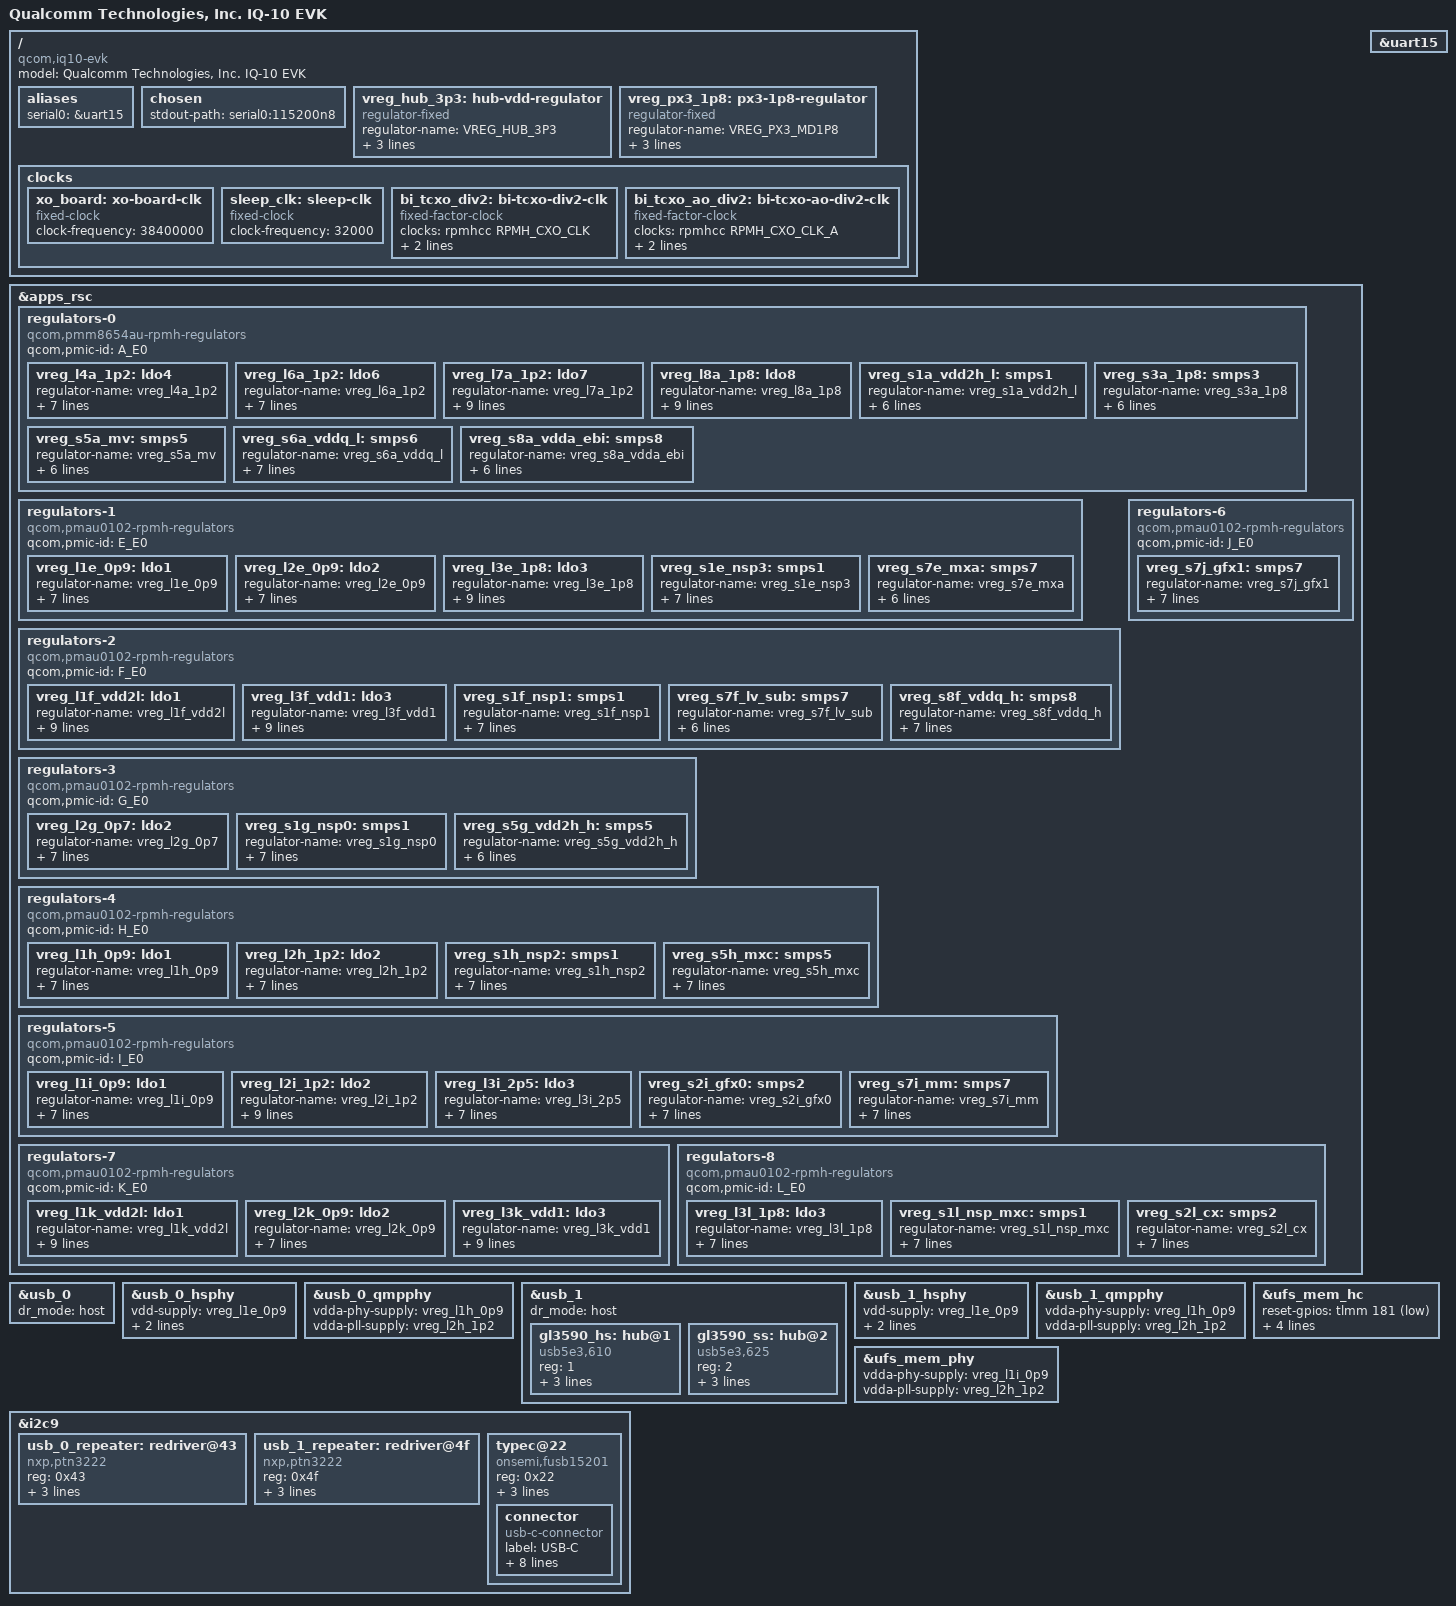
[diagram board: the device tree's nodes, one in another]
// SPDX-License-Identifier: BSD-3-Clause
/*
 * Copyright (c) 2024-2025, Qualcomm Innovation Center, Inc. All rights reserved.
 */

/dts-v1/;

#include <dt-bindings/gpio/gpio.h>
#include <dt-bindings/regulator/qcom,rpmh-regulator.h>
#include <dt-bindings/usb/pd.h>

#include "nord-iq10.dtsi"

/ {
	model = "Qualcomm Technologies, Inc. IQ-10 EVK";
	compatible = "qcom,iq10-evk", "qcom,iq10", "qcom,nord";

	aliases {
		serial0 = &uart15;
	};

	chosen {
		stdout-path = "serial0:115200n8";
	};

	/*
	 * The GL3590 hub's VDD (3.3V) comes from a dedicated always-on board
	 * rail (VREG_PER_3P3) — there is no PMIC LDO behind it.
	 */
	vreg_hub_3p3: hub-vdd-regulator {
		compatible = "regulator-fixed";
		regulator-name = "VREG_HUB_3P3";
		regulator-min-microvolt = <3300000>;
		regulator-max-microvolt = <3300000>;
		regulator-always-on;
	};

	/*
	 * VREG_PX3_MD1P8 (1.8V): TPS6594742 UPMS PMIC SMPS5 output
	 * (VDD_SAIL_PX3_VREG_S1P8). The TPS6594742 is managed by the SAIL
	 * RTOS over SAIL I2C (SGP0/1); the main SoC Linux kernel has no
	 * direct path to it. Describe as a fixed always-on stub — SAIL
	 * firmware enables SMPS5 unconditionally at startup.
	 * Powers: FUSB15201 VDD (U15) and its I2C level shifter VCCA (U17).
	 */
	vreg_px3_1p8: px3-1p8-regulator {
		compatible = "regulator-fixed";
		regulator-name = "VREG_PX3_MD1P8";
		regulator-min-microvolt = <1800000>;
		regulator-max-microvolt = <1800000>;
		regulator-always-on;
	};

	clocks {
		xo_board: xo-board-clk {
			compatible = "fixed-clock";
			clock-frequency = <38400000>;
			#clock-cells = <0>;
		};

		sleep_clk: sleep-clk {
			compatible = "fixed-clock";
			clock-frequency = <32000>;
			#clock-cells = <0>;
		};

		bi_tcxo_div2: bi-tcxo-div2-clk {
			compatible = "fixed-factor-clock";
			#clock-cells = <0>;
			clocks = <&rpmhcc RPMH_CXO_CLK>;
			clock-mult = <1>;
			clock-div = <2>;
		};

		bi_tcxo_ao_div2: bi-tcxo-ao-div2-clk {
			compatible = "fixed-factor-clock";
			#clock-cells = <0>;
			clocks = <&rpmhcc RPMH_CXO_CLK_A>;
			clock-mult = <1>;
			clock-div = <2>;
		};
	};
};

&apps_rsc {
	/* PMIC A - Kobra_MM (PMM8650AU) - SID 0x0, Bus E0 */
	regulators-0 {
		compatible = "qcom,pmm8654au-rpmh-regulators";
		qcom,pmic-id = "A_E0";

		/* LDO Regulators */
		vreg_l4a_1p2: ldo4 {
			regulator-name = "vreg_l4a_1p2";
			regulator-min-microvolt = <1200000>;
			regulator-max-microvolt = <1200000>;
			regulator-initial-mode = <RPMH_REGULATOR_MODE_HPM>;
			regulator-allow-set-load;
			regulator-allowed-modes = <RPMH_REGULATOR_MODE_LPM
						   RPMH_REGULATOR_MODE_HPM>;
		};

		vreg_l6a_1p2: ldo6 {
			regulator-name = "vreg_l6a_1p2";
			regulator-min-microvolt = <1200000>;
			regulator-max-microvolt = <1200000>;
			regulator-initial-mode = <RPMH_REGULATOR_MODE_HPM>;
			regulator-allow-set-load;
			regulator-allowed-modes = <RPMH_REGULATOR_MODE_LPM
						   RPMH_REGULATOR_MODE_HPM>;
		};

		vreg_l7a_1p2: ldo7 {
			regulator-name = "vreg_l7a_1p2";
			regulator-min-microvolt = <1200000>;
			regulator-max-microvolt = <1200000>;
			regulator-initial-mode = <RPMH_REGULATOR_MODE_HPM>;
			regulator-always-on;
			regulator-boot-on;
			regulator-allow-set-load;
			regulator-allowed-modes = <RPMH_REGULATOR_MODE_LPM
						   RPMH_REGULATOR_MODE_HPM>;
		};

		vreg_l8a_1p8: ldo8 {
			regulator-name = "vreg_l8a_1p8";
			regulator-min-microvolt = <1800000>;
			regulator-max-microvolt = <1800000>;
			regulator-initial-mode = <RPMH_REGULATOR_MODE_HPM>;
			regulator-always-on;
			regulator-boot-on;
			regulator-allow-set-load;
			regulator-allowed-modes = <RPMH_REGULATOR_MODE_LPM
						   RPMH_REGULATOR_MODE_HPM>;
		};

		/* SMPS Regulators */
		vreg_s1a_vdd2h_l: smps1 {
			regulator-name = "vreg_s1a_vdd2h_l";
			regulator-min-microvolt = <900000>;
			regulator-max-microvolt = <1100000>;
			regulator-initial-mode = <RPMH_REGULATOR_MODE_HPM>;
			regulator-always-on;
			regulator-boot-on;
		};

		vreg_s3a_1p8: smps3 {
			regulator-name = "vreg_s3a_1p8";
			regulator-min-microvolt = <1800000>;
			regulator-max-microvolt = <1800000>;
			regulator-initial-mode = <RPMH_REGULATOR_MODE_HPM>;
			regulator-always-on;
			regulator-boot-on;
		};

		vreg_s5a_mv: smps5 {
			regulator-name = "vreg_s5a_mv";
			regulator-min-microvolt = <1328000>;
			regulator-max-microvolt = <1370000>;
			regulator-initial-mode = <RPMH_REGULATOR_MODE_HPM>;
			regulator-always-on;
			regulator-boot-on;
		};

		vreg_s6a_vddq_l: smps6 {
			regulator-name = "vreg_s6a_vddq_l";
			regulator-min-microvolt = <500000>;
			regulator-max-microvolt = <570000>;
			regulator-initial-mode = <RPMH_REGULATOR_MODE_HPM>;
			regulator-allow-set-load;
			regulator-allowed-modes = <RPMH_REGULATOR_MODE_LPM
						   RPMH_REGULATOR_MODE_HPM>;
		};

		vreg_s8a_vdda_ebi: smps8 {
			regulator-name = "vreg_s8a_vdda_ebi";
			regulator-min-microvolt = <300000>;
			regulator-max-microvolt = <1200000>;
			regulator-initial-mode = <RPMH_REGULATOR_MODE_HPM>;
			regulator-always-on;
			regulator-boot-on;
		};
	};

	/* PMIC E - Kai_MV - SID 0x4, Bus E0 */
	regulators-1 {
		compatible = "qcom,pmau0102-rpmh-regulators";
		qcom,pmic-id = "E_E0";

		/* LDO Regulators */
		vreg_l1e_0p9: ldo1 {
			regulator-name = "vreg_l1e_0p9";
			regulator-min-microvolt = <936000>;
			regulator-max-microvolt = <936000>;
			regulator-initial-mode = <RPMH_REGULATOR_MODE_HPM>;
			regulator-allow-set-load;
			regulator-allowed-modes = <RPMH_REGULATOR_MODE_LPM
						   RPMH_REGULATOR_MODE_HPM>;
		};

		vreg_l2e_0p9: ldo2 {
			regulator-name = "vreg_l2e_0p9";
			regulator-min-microvolt = <936000>;
			regulator-max-microvolt = <936000>;
			regulator-initial-mode = <RPMH_REGULATOR_MODE_HPM>;
			regulator-allow-set-load;
			regulator-allowed-modes = <RPMH_REGULATOR_MODE_LPM
						   RPMH_REGULATOR_MODE_HPM>;
		};

		vreg_l3e_1p8: ldo3 {
			regulator-name = "vreg_l3e_1p8";
			regulator-min-microvolt = <1800000>;
			regulator-max-microvolt = <1800000>;
			regulator-initial-mode = <RPMH_REGULATOR_MODE_HPM>;
			regulator-always-on;
			regulator-boot-on;
			regulator-allow-set-load;
			regulator-allowed-modes = <RPMH_REGULATOR_MODE_LPM
						   RPMH_REGULATOR_MODE_HPM>;
		};

		/* SMPS Regulators */
		vreg_s1e_nsp3: smps1 {
			regulator-name = "vreg_s1e_nsp3";
			regulator-min-microvolt = <300000>;
			regulator-max-microvolt = <1200000>;
			regulator-initial-mode = <RPMH_REGULATOR_MODE_HPM>;
			regulator-allow-set-load;
			regulator-allowed-modes = <RPMH_REGULATOR_MODE_LPM
						   RPMH_REGULATOR_MODE_HPM>;
		};

		vreg_s7e_mxa: smps7 {
			regulator-name = "vreg_s7e_mxa";
			regulator-min-microvolt = <300000>;
			regulator-max-microvolt = <1200000>;
			regulator-initial-mode = <RPMH_REGULATOR_MODE_HPM>;
			regulator-always-on;
			regulator-boot-on;
		};
	};

	/* PMIC F - Kai_MV - SID 0x5, Bus E0 */
	regulators-2 {
		compatible = "qcom,pmau0102-rpmh-regulators";
		qcom,pmic-id = "F_E0";

		/* LDO Regulators */
		vreg_l1f_vdd2l: ldo1 {
			regulator-name = "vreg_l1f_vdd2l";
			regulator-min-microvolt = <904000>;
			regulator-max-microvolt = <904000>;
			regulator-initial-mode = <RPMH_REGULATOR_MODE_HPM>;
			regulator-always-on;
			regulator-boot-on;
			regulator-allow-set-load;
			regulator-allowed-modes = <RPMH_REGULATOR_MODE_LPM
						   RPMH_REGULATOR_MODE_HPM>;
		};

		vreg_l3f_vdd1: ldo3 {
			regulator-name = "vreg_l3f_vdd1";
			regulator-min-microvolt = <1800000>;
			regulator-max-microvolt = <1800000>;
			regulator-initial-mode = <RPMH_REGULATOR_MODE_HPM>;
			regulator-always-on;
			regulator-boot-on;
			regulator-allow-set-load;
			regulator-allowed-modes = <RPMH_REGULATOR_MODE_LPM
						   RPMH_REGULATOR_MODE_HPM>;
		};

		/* SMPS Regulators */
		vreg_s1f_nsp1: smps1 {
			regulator-name = "vreg_s1f_nsp1";
			regulator-min-microvolt = <300000>;
			regulator-max-microvolt = <1200000>;
			regulator-initial-mode = <RPMH_REGULATOR_MODE_HPM>;
			regulator-allow-set-load;
			regulator-allowed-modes = <RPMH_REGULATOR_MODE_LPM
						   RPMH_REGULATOR_MODE_HPM>;
		};

		vreg_s7f_lv_sub: smps7 {
			regulator-name = "vreg_s7f_lv_sub";
			regulator-min-microvolt = <1036000>;
			regulator-max-microvolt = <1136000>;
			regulator-initial-mode = <RPMH_REGULATOR_MODE_HPM>;
			regulator-always-on;
			regulator-boot-on;
		};

		vreg_s8f_vddq_h: smps8 {
			regulator-name = "vreg_s8f_vddq_h";
			regulator-min-microvolt = <500000>;
			regulator-max-microvolt = <570000>;
			regulator-initial-mode = <RPMH_REGULATOR_MODE_HPM>;
			regulator-allow-set-load;
			regulator-allowed-modes = <RPMH_REGULATOR_MODE_LPM
						   RPMH_REGULATOR_MODE_HPM>;
		};
	};

	/* PMIC G - Kai_MV - SID 0x6, Bus E0 */
	regulators-3 {
		compatible = "qcom,pmau0102-rpmh-regulators";
		qcom,pmic-id = "G_E0";

		/* LDO Regulators */
		vreg_l2g_0p7: ldo2 {
			regulator-name = "vreg_l2g_0p7";
			regulator-min-microvolt = <752000>;
			regulator-max-microvolt = <752000>;
			regulator-initial-mode = <RPMH_REGULATOR_MODE_HPM>;
			regulator-allow-set-load;
			regulator-allowed-modes = <RPMH_REGULATOR_MODE_LPM
						   RPMH_REGULATOR_MODE_HPM>;
		};

		/* SMPS Regulators */
		vreg_s1g_nsp0: smps1 {
			regulator-name = "vreg_s1g_nsp0";
			regulator-min-microvolt = <300000>;
			regulator-max-microvolt = <1200000>;
			regulator-initial-mode = <RPMH_REGULATOR_MODE_HPM>;
			regulator-allow-set-load;
			regulator-allowed-modes = <RPMH_REGULATOR_MODE_LPM
						   RPMH_REGULATOR_MODE_HPM>;
		};

		vreg_s5g_vdd2h_h: smps5 {
			regulator-name = "vreg_s5g_vdd2h_h";
			regulator-min-microvolt = <1080000>;
			regulator-max-microvolt = <1150000>;
			regulator-initial-mode = <RPMH_REGULATOR_MODE_HPM>;
			regulator-always-on;
			regulator-boot-on;
		};
	};

	/* PMIC H - Kai_MV - SID 0x7, Bus E0 */
	regulators-4 {
		compatible = "qcom,pmau0102-rpmh-regulators";
		qcom,pmic-id = "H_E0";

		/* LDO Regulators */
		vreg_l1h_0p9: ldo1 {
			regulator-name = "vreg_l1h_0p9";
			regulator-min-microvolt = <904000>;
			regulator-max-microvolt = <904000>;
			regulator-initial-mode = <RPMH_REGULATOR_MODE_HPM>;
			regulator-allow-set-load;
			regulator-allowed-modes = <RPMH_REGULATOR_MODE_LPM
						   RPMH_REGULATOR_MODE_HPM>;
		};

		vreg_l2h_1p2: ldo2 {
			regulator-name = "vreg_l2h_1p2";
			regulator-min-microvolt = <1200000>;
			regulator-max-microvolt = <1200000>;
			regulator-initial-mode = <RPMH_REGULATOR_MODE_HPM>;
			regulator-allow-set-load;
			regulator-allowed-modes = <RPMH_REGULATOR_MODE_LPM
						   RPMH_REGULATOR_MODE_HPM>;
		};

		/* SMPS Regulators */
		vreg_s1h_nsp2: smps1 {
			regulator-name = "vreg_s1h_nsp2";
			regulator-min-microvolt = <300000>;
			regulator-max-microvolt = <1200000>;
			regulator-initial-mode = <RPMH_REGULATOR_MODE_HPM>;
			regulator-allow-set-load;
			regulator-allowed-modes = <RPMH_REGULATOR_MODE_LPM
						   RPMH_REGULATOR_MODE_HPM>;
		};

		vreg_s5h_mxc: smps5 {
			regulator-name = "vreg_s5h_mxc";
			regulator-min-microvolt = <300000>;
			regulator-max-microvolt = <1200000>;
			regulator-initial-mode = <RPMH_REGULATOR_MODE_HPM>;
			regulator-allow-set-load;
			regulator-allowed-modes = <RPMH_REGULATOR_MODE_LPM
						   RPMH_REGULATOR_MODE_HPM>;
		};
	};

	/* PMIC I - Kai_MV - SID 0x8, Bus E0 */
	regulators-5 {
		compatible = "qcom,pmau0102-rpmh-regulators";
		qcom,pmic-id = "I_E0";

		/* LDO Regulators */
		vreg_l1i_0p9: ldo1 {
			regulator-name = "vreg_l1i_0p9";
			regulator-min-microvolt = <912000>;
			regulator-max-microvolt = <912000>;
			regulator-initial-mode = <RPMH_REGULATOR_MODE_HPM>;
			regulator-allow-set-load;
			regulator-allowed-modes = <RPMH_REGULATOR_MODE_LPM
						   RPMH_REGULATOR_MODE_HPM>;
		};

		vreg_l2i_1p2: ldo2 {
			regulator-name = "vreg_l2i_1p2";
			regulator-min-microvolt = <1200000>;
			regulator-max-microvolt = <1200000>;
			regulator-initial-mode = <RPMH_REGULATOR_MODE_HPM>;
			regulator-always-on;
			regulator-boot-on;
			regulator-allow-set-load;
			regulator-allowed-modes = <RPMH_REGULATOR_MODE_LPM
						   RPMH_REGULATOR_MODE_HPM>;
		};

		vreg_l3i_2p5: ldo3 {
			regulator-name = "vreg_l3i_2p5";
			regulator-min-microvolt = <2504000>;
			regulator-max-microvolt = <2504000>;
			regulator-initial-mode = <RPMH_REGULATOR_MODE_HPM>;
			regulator-allow-set-load;
			regulator-allowed-modes = <RPMH_REGULATOR_MODE_LPM
						   RPMH_REGULATOR_MODE_HPM>;
		};

		/* SMPS Regulators */
		vreg_s2i_gfx0: smps2 {
			regulator-name = "vreg_s2i_gfx0";
			regulator-min-microvolt = <300000>;
			regulator-max-microvolt = <1200000>;
			regulator-initial-mode = <RPMH_REGULATOR_MODE_HPM>;
			regulator-allow-set-load;
			regulator-allowed-modes = <RPMH_REGULATOR_MODE_LPM
						   RPMH_REGULATOR_MODE_HPM>;
		};

		vreg_s7i_mm: smps7 {
			regulator-name = "vreg_s7i_mm";
			regulator-min-microvolt = <300000>;
			regulator-max-microvolt = <1200000>;
			regulator-initial-mode = <RPMH_REGULATOR_MODE_HPM>;
			regulator-allow-set-load;
			regulator-allowed-modes = <RPMH_REGULATOR_MODE_LPM
						   RPMH_REGULATOR_MODE_HPM>;
		};
	};

	/* PMIC J - Kai_MV - SID 0x9, Bus E0 */
	regulators-6 {
		compatible = "qcom,pmau0102-rpmh-regulators";
		qcom,pmic-id = "J_E0";

		/* SMPS Regulators */
		vreg_s7j_gfx1: smps7 {
			regulator-name = "vreg_s7j_gfx1";
			regulator-min-microvolt = <300000>;
			regulator-max-microvolt = <1200000>;
			regulator-initial-mode = <RPMH_REGULATOR_MODE_HPM>;
			regulator-allow-set-load;
			regulator-allowed-modes = <RPMH_REGULATOR_MODE_LPM
						   RPMH_REGULATOR_MODE_HPM>;
		};
	};

	/* PMIC K - Kai_MV - SID 0xA, Bus E0 */
	regulators-7 {
		compatible = "qcom,pmau0102-rpmh-regulators";
		qcom,pmic-id = "K_E0";

		/* LDO Regulators */
		vreg_l1k_vdd2l: ldo1 {
			regulator-name = "vreg_l1k_vdd2l";
			regulator-min-microvolt = <904000>;
			regulator-max-microvolt = <904000>;
			regulator-initial-mode = <RPMH_REGULATOR_MODE_HPM>;
			regulator-always-on;
			regulator-boot-on;
			regulator-allow-set-load;
			regulator-allowed-modes = <RPMH_REGULATOR_MODE_LPM
						   RPMH_REGULATOR_MODE_HPM>;
		};

		vreg_l2k_0p9: ldo2 {
			regulator-name = "vreg_l2k_0p9";
			regulator-min-microvolt = <880000>;
			regulator-max-microvolt = <880000>;
			regulator-initial-mode = <RPMH_REGULATOR_MODE_HPM>;
			regulator-allow-set-load;
			regulator-allowed-modes = <RPMH_REGULATOR_MODE_LPM
						   RPMH_REGULATOR_MODE_HPM>;
		};

		vreg_l3k_vdd1: ldo3 {
			regulator-name = "vreg_l3k_vdd1";
			regulator-min-microvolt = <1800000>;
			regulator-max-microvolt = <1800000>;
			regulator-initial-mode = <RPMH_REGULATOR_MODE_HPM>;
			regulator-always-on;
			regulator-boot-on;
			regulator-allow-set-load;
			regulator-allowed-modes = <RPMH_REGULATOR_MODE_LPM
						   RPMH_REGULATOR_MODE_HPM>;
		};
	};

	/* PMIC L - Kai_MV - SID 0xB, Bus E0 */
	regulators-8 {
		compatible = "qcom,pmau0102-rpmh-regulators";
		qcom,pmic-id = "L_E0";

		/* LDO Regulators */
		vreg_l3l_1p8: ldo3 {
			regulator-name = "vreg_l3l_1p8";
			regulator-min-microvolt = <1800000>;
			regulator-max-microvolt = <1800000>;
			regulator-initial-mode = <RPMH_REGULATOR_MODE_HPM>;
			regulator-allow-set-load;
			regulator-allowed-modes = <RPMH_REGULATOR_MODE_LPM
						   RPMH_REGULATOR_MODE_HPM>;
		};

		/* SMPS Regulators */
		vreg_s1l_nsp_mxc: smps1 {
			regulator-name = "vreg_s1l_nsp_mxc";
			regulator-min-microvolt = <300000>;
			regulator-max-microvolt = <1200000>;
			regulator-initial-mode = <RPMH_REGULATOR_MODE_HPM>;
			regulator-allow-set-load;
			regulator-allowed-modes = <RPMH_REGULATOR_MODE_LPM
						   RPMH_REGULATOR_MODE_HPM>;
		};

		vreg_s2l_cx: smps2 {
			regulator-name = "vreg_s2l_cx";
			regulator-min-microvolt = <300000>;
			regulator-max-microvolt = <1200000>;
			regulator-initial-mode = <RPMH_REGULATOR_MODE_HPM>;
			regulator-allow-set-load;
			regulator-allowed-modes = <RPMH_REGULATOR_MODE_LPM
						   RPMH_REGULATOR_MODE_HPM>;
		};
	};
};

&uart15 {
	status = "okay";
};

/*
 * TODO: PHY supply rails are provisional, chosen to match the eUSB2 / QMP
 * USB3-DP binding requirements from the EVK PMIC rails. Confirm against the
 * board schematics.
 */
&usb_0 {
	dr_mode = "host";
	status = "okay";
};

&usb_0_hsphy {
	vdd-supply = <&vreg_l1e_0p9>;
	vdda12-supply = <&vreg_l2i_1p2>;
	phys = <&usb_0_repeater>;
	phy-names = "usb2-phy";
	status = "okay";
};

&usb_0_qmpphy {
	vdda-phy-supply = <&vreg_l1h_0p9>;
	vdda-pll-supply = <&vreg_l2h_1p2>;
	status = "okay";
};

&usb_1 {
	dr_mode = "host";
	status = "okay";

	#address-cells = <1>;
	#size-cells = <0>;

	/*
	 * Genesys Logic GL3590 USB3.2 4-port hub (U13).
	 * Upstream port connects to the SoC's usb_1 controller.
	 * Reset is shared between the HS and SS hub instances (GPIO170,
	 * active-low). VDD12 (1.2V) is shared with USB PHY PLL rail.
	 */
	gl3590_hs: hub@1 {
		compatible = "usb5e3,610";
		reg = <1>;
		reset-gpios = <&tlmm 170 GPIO_ACTIVE_LOW>;
		vdd-supply = <&vreg_hub_3p3>;
		peer-hub = <&gl3590_ss>;
	};

	gl3590_ss: hub@2 {
		compatible = "usb5e3,625";
		reg = <2>;
		vdd-supply = <&vreg_hub_3p3>;
		vdd12-supply = <&vreg_l2i_1p2>;
		peer-hub = <&gl3590_hs>;
	};
};

&usb_1_hsphy {
	vdd-supply = <&vreg_l1e_0p9>;
	vdda12-supply = <&vreg_l2i_1p2>;
	phys = <&usb_1_repeater>;
	phy-names = "usb2-phy";
	status = "okay";
};

&usb_1_qmpphy {
	vdda-phy-supply = <&vreg_l1h_0p9>;
	vdda-pll-supply = <&vreg_l2h_1p2>;
	status = "okay";
};

/*
 * i2c9 (QUP1_SE2, GPIO127/128): USB-related I2C peripherals.
 *  - U12/U211: NXP PTN3222 eUSB2 repeaters (reset via PMIC I GPIOs 9/10)
 *  - U15: onsemi FUSB15201 Type-C PD controller for connector "0" (JUSB0)
 *         (interrupt via PMIC I GPIO 8, I2C address 0x22)
 */
&i2c9 {
	status = "okay";

	usb_0_repeater: redriver@43 {
		compatible = "nxp,ptn3222";
		reg = <0x43>;
		#phy-cells = <0>;
		vdd3v3-supply = <&vreg_hub_3p3>;
		vdd1v8-supply = <&vreg_l3e_1p8>;
		reset-gpios = <&pmic_i_gpios 8 GPIO_ACTIVE_LOW>;
	};

	usb_1_repeater: redriver@4f {
		compatible = "nxp,ptn3222";
		reg = <0x4f>;
		#phy-cells = <0>;
		vdd3v3-supply = <&vreg_hub_3p3>;
		vdd1v8-supply = <&vreg_l3e_1p8>;
		reset-gpios = <&pmic_i_gpios 9 GPIO_ACTIVE_LOW>;
	};

	typec@22 {
		compatible = "onsemi,fusb15201", "tcpci";
		reg = <0x22>;
		interrupt-parent = <&pmic_i_gpios>;
		interrupts = <7 IRQ_TYPE_LEVEL_LOW>;
		vdd-supply = <&vreg_px3_1p8>;

		connector {
			compatible = "usb-c-connector";
			label = "USB-C";
			data-role = "dual";
			power-role = "dual";
			try-power-role = "sink";
			source-pdos = <PDO_FIXED(5000, 900, PDO_FIXED_USB_COMM)>;
			sink-pdos = <PDO_FIXED(5000, 3000, PDO_FIXED_USB_COMM)>;
			op-sink-microwatt = <10000000>;
		};
	};
};

/*
 * usb_2 (USB2.0 HS-only @0xa200000) is not wired to anything on the IQ-10
 * board — its eUSB2 lines (EUSB2_EDP/EDM) terminate unrouted. The SoC node
 * stays defined in nord.dtsi; it is simply left disabled here. Enabling it
 * (with the PHY unconnected) hangs the system at xhci registration.
 */

&ufs_mem_hc {
	reset-gpios = <&tlmm 181 GPIO_ACTIVE_LOW>;

	vcc-supply = <&vreg_l3i_2p5>;
	vcc-max-microamp = <1300000>;
	vccq-supply = <&vreg_l2i_1p2>;
	vccq-max-microamp = <1200000>;
	status = "okay";
};

&ufs_mem_phy {
	vdda-phy-supply = <&vreg_l1i_0p9>;
	vdda-pll-supply = <&vreg_l2h_1p2>;
	status = "okay";
};
